# STM32U5xx register map
File version: 1.3
Registers are 32-bit, read-write, reset 0x0 unless marked. A register's access mark holds for its fields unless they carry their own. Offsets are from the block's base; [hi:lo] are bit positions; {n}, {i} and the like mark numbered series.

## ADF1
Base 0x46024000
Same registers: SEC_ADF1 0x56024000
0x00 ADF_GCR — ADF Global Control Register
  [0] TRGO — Trigger output control Set by software and reset by
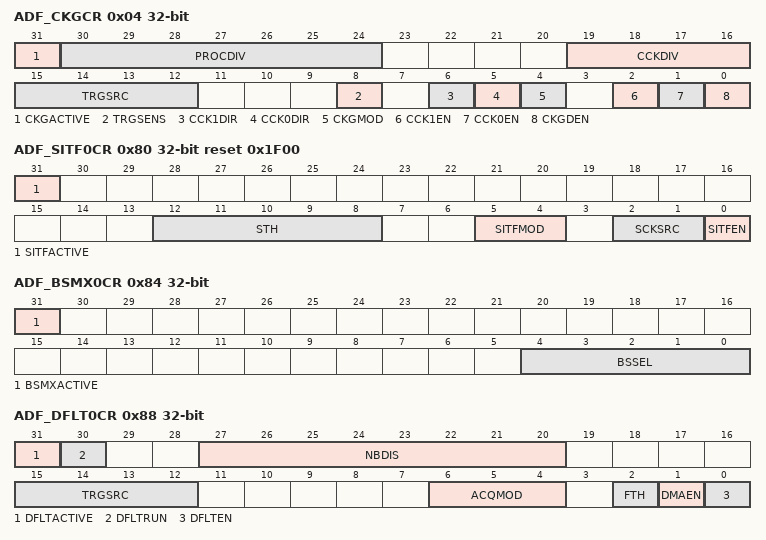
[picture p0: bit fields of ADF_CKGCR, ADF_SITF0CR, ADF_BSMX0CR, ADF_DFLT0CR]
0x04 ADF_CKGCR — ADF clock generator control register
  [31] CKGACTIVE — Clock generator active flag
  [30:24] PROCDIV — Divider to control the serial interface clock
  [19:16] CCKDIV — Divider to control the ADF_CCK clock
  [15:12] TRGSRC — Digital filter trigger signal selection
  [8] TRGSENS — CKGEN trigger sensitivity selection
  [6] CCK1DIR — ADF_CCK1 direction
  [5] CCK0DIR — ADF_CCK0 direction
  [4] CKGMOD — Clock generator mode
  [2] CCK1EN — ADF_CCK1 clock enable
  [1] CCK0EN — ADF_CCK0 clock enable
  [0] CKGDEN — CKGEN dividers enable
0x80 ADF_SITF0CR reset 0x1F00 — ADF serial interface control register 0
  [31] SITFACTIVE, [12:8] STH, [5:4] SITFMOD, [2:1] SCKSRC, [0] SITFEN
0x84 ADF_BSMX0CR — ADF bitstream matrix control register 0
  [31] BSMXACTIVE — BSMX active flag
  [4:0] BSSEL — Bitstream selection
0x88 ADF_DFLT0CR — ADF digital filter control register 0
  [31] DFLTACTIVE — DFLT0 active flag
  [30] DFLTRUN — DFLT0 run status flag
  [27:20] NBDIS — Number of samples to be discarded
  [15:12] TRGSRC — DFLT0 trigger signal selection
  [6:4] ACQMOD — DFLT0 trigger mode
  [2] FTH — RXFIFO threshold selection
  [1] DMAEN — DMA requests enable
  [0] DFLTEN — DFLT0 enable
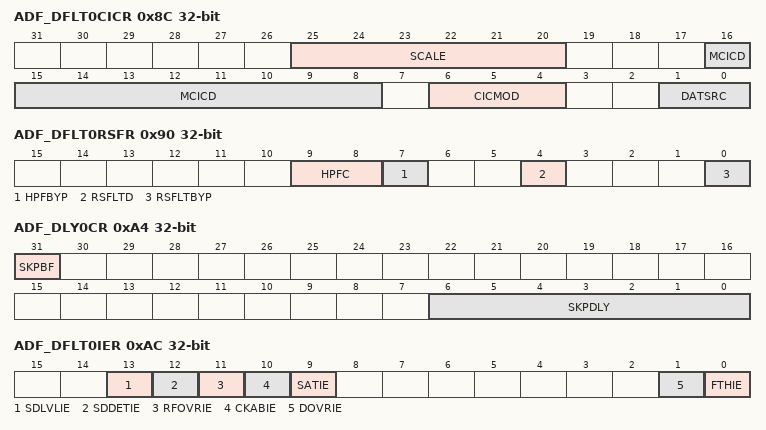
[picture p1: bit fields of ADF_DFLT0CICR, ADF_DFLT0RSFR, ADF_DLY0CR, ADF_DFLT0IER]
0x8C ADF_DFLT0CICR — ADF digital filer configuration register 0
  [25:20] SCALE — Scaling factor selection
  [16:8] MCICD — CIC decimation ratio selection
  [6:4] CICMOD — Select the CIC order
  [1:0] DATSRC — Source data for the digital filter
0x90 ADF_DFLT0RSFR — ADF reshape filter configuration register 0
  [9:8] HPFC — High-pass filter cut-off frequency
  [7] HPFBYP — High-pass filter bypass
  [4] RSFLTD — Reshaper filter decimation ratio
  [0] RSFLTBYP — Reshaper filter bypass
0xA4 ADF_DLY0CR — ADF delay control register 0
  [31] SKPBF — Skip busy flag
  [6:0] SKPDLY — Delay to apply to a bitstream
0xAC ADF_DFLT0IER — ADF DFLT0 interrupt enable register
  [13] SDLVLIE — SAD sound-level value ready enable
  [12] SDDETIE — Sound activity detection interrupt enable
  [11] RFOVRIE — Reshape filter overrun interrupt enable
  [10] CKABIE — Clock absence detection interrupt enable
  [9] SATIE — Saturation detection interrupt enable
  [1] DOVRIE — Data overflow interrupt enable
  [0] FTHIE — RXFIFO threshold interrupt enable
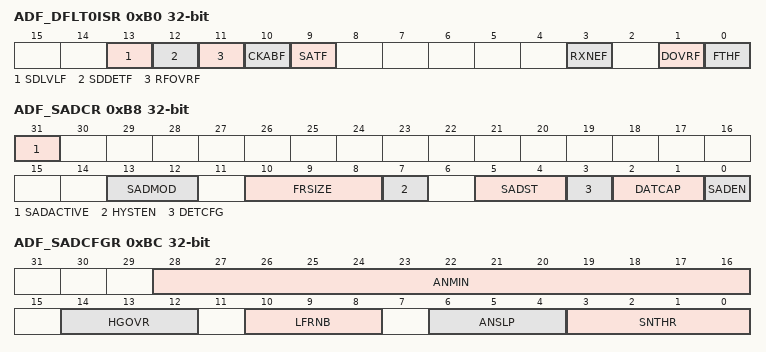
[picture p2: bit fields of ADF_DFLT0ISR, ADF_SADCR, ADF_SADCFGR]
0xB0 ADF_DFLT0ISR access per field — ADF DFLT0 interrupt status register 0
  [13] SDLVLF rw — Sound level value ready flag
  [12] SDDETF rw — Sound activity detection flag
  [11] RFOVRF rw — Reshape filter overrun detection flag
  [10] CKABF rw — Clock absence detection flag
  [9] SATF rw — Saturation detection flag
  [3] RXNEF ro — RXFIFO not empty flag
  [1] DOVRF rw — Data overflow flag
  [0] FTHF ro — RXFIFO threshold flag
0xB8 ADF_SADCR access per field — ADF SAD control register
  [31] SADACTIVE ro — SAD Active flag
  [13:12] SADMOD rw — SAD working mode
  [10:8] FRSIZE rw — Frame size
  [7] HYSTEN rw — Hysteresis enable
  [5:4] SADST ro — SAD state
  [3] DETCFG rw — Sound trigger event configuration
  [2:1] DATCAP rw — Data capture mode
  [0] SADEN rw — Sound activity detector enable
0xBC ADF_SADCFGR — ADF SAD configuration register
  [28:16] ANMIN
  [14:12] HGOVR — Hangover time window
  [10:8] LFRNB
  [6:4] ANSLP
  [3:0] SNTHR
0xC0 ADF_SADSDLVR ro — ADF SAD sound level register
  [14:0] SDLVL
0xC4 ADF_SADANLVR ro — ADF SAD ambient noise level register
  [14:0] ANLVL
0xF0 ADF_DFLT0DR ro — ADF digital filter data register 0
  [31:8] DR

## LPGPIO1
Base 0x46020000
Same registers: SEC_LPGPIO1 0x56020000
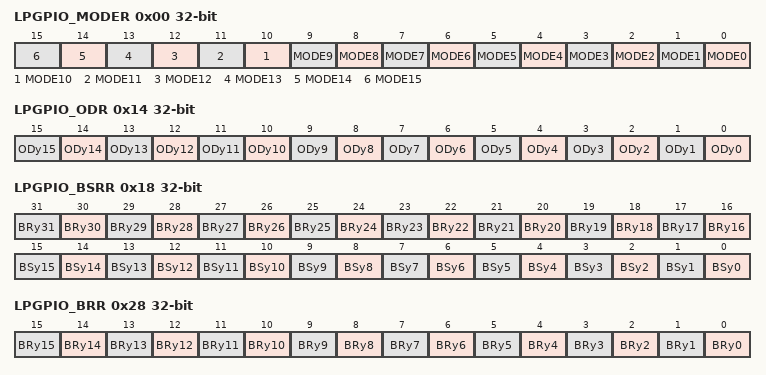
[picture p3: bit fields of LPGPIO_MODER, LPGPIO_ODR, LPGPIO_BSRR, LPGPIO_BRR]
0x00 LPGPIO_MODER — LPGPIO port mode register
  [n] MODE{n} (n=0..15)
0x10 LPGPIO_IDR ro — LPGPIO port input data register
  [15:0] IDy
0x14 LPGPIO_ODR — LPGPIO port output data register
  [n] ODy{n} (n=0..15)
0x18 LPGPIO_BSRR wo — LPGPIO port bit set/reset register
  [n] BRy{n} (n=16..31), [n] BSy{n} (n=0..15)
0x28 LPGPIO_BRR ro — LPGPIO port bit reset register
  [n] BRy{n} (n=0..15)
